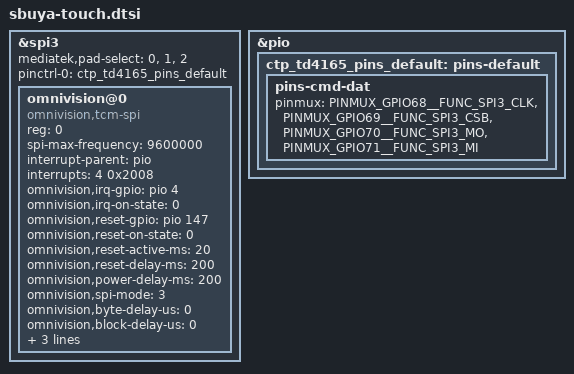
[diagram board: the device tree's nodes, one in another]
// SPDX-License-Identifier: (GPL-2.0 OR MIT)
/*
 * Copyright (c) 2024, Motorola Mobility Inc. All rights reserved.
*/

&spi3 {
	status = "okay";
	#address-cells = <1>;
	#size-cells = <0>;
	mediatek,pad-select = <0>, <1>, <2>;
	pinctrl-names = "default";

	pinctrl-0 = <&ctp_td4165_pins_default>;

	/* omnivision device tree node */
	omnivision@0 {
		compatible = "omnivision,tcm-spi";
		reg = <0>; //Same as CS ID
		status = "ok";
		spi-max-frequency = <9600000>;
		interrupt-parent = <&pio>;
		interrupts = <4 0x2008>;

		omnivision,irq-gpio = <&pio 4 0x00>;
		omnivision,irq-on-state = <0>;
		omnivision,reset-gpio = <&pio 147 0x00>;
		omnivision,reset-on-state = <0>;
		omnivision,reset-active-ms = <20>;
		omnivision,reset-delay-ms = <200>;
		omnivision,power-delay-ms = <200>;
		omnivision,spi-mode = <3>;
		omnivision,byte-delay-us = <0>;
		omnivision,block-delay-us = <0>;
		omnivision,ubl-max-freq = <3000000>;
		omnivision,ubl-byte-delay-us = <20>;

		omnivision,supported_gesture_type = <0x04>;
        };
};

&pio {
	ctp_td4165_pins_default: pins-default {
		pins-cmd-dat {
			pinmux = <PINMUX_GPIO68__FUNC_SPI3_CLK>,
				<PINMUX_GPIO69__FUNC_SPI3_CSB>,
				<PINMUX_GPIO70__FUNC_SPI3_MO>,
				<PINMUX_GPIO71__FUNC_SPI3_MI>;
		};


	};
};

/* TOUCH end */
